# STM32H562 register map
File version: 1.7
CPU: CM33 r0p0, little endian, MPU, FPU, 4 interrupt priority bits
Registers are 32-bit, read-write, reset 0x0 unless marked. A register's access mark holds for its fields unless they carry their own. Offsets are from the block's base; [hi:lo] are bit positions; {n}, {i} and the like mark numbered series; 'fields as' and 'values as' point back to an identical list.

## FMC — Flexible memory controller
Base 0x47000400
Same registers: SEC_FMC 0x57000400
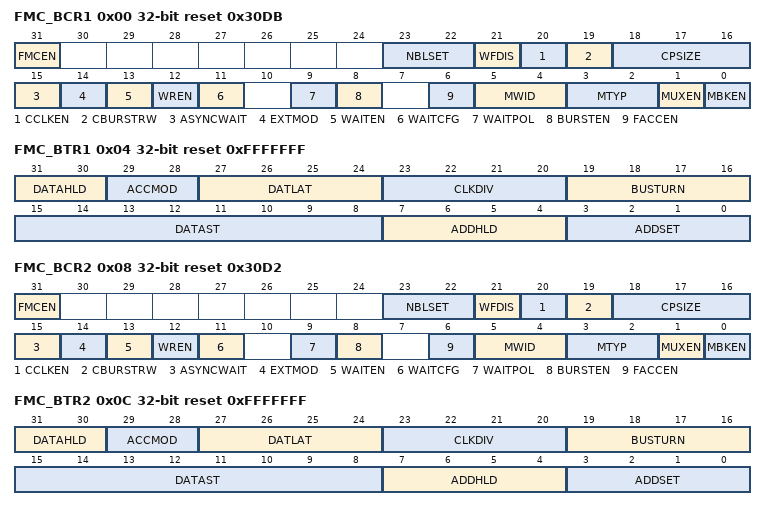
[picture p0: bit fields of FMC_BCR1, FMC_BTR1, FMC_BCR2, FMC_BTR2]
0x00 FMC_BCR1 reset 0x30DB — SRAM/NOR-Flash chip-select control register for bank 1
  [31] FMCEN — FMC controller enable This bit enables or disables the FMC controller. Note: The FMCEN bit of the FMC_BCR2..4 registers is don't care. It is only enabled through the FMC_BCR1 register.
    0=Disable the FMC controller; 1=Enable the FMC controller
  [23:22] NBLSET — Byte lane (NBL) setup These bits configure the NBL setup timing from NBLx low to chip select NEx low.
    0=NBL setup time is 0 AHB clock cycle; 1=NBL setup time is 1 AHB clock cycle; 2=NBL setup time is 2 AHB clock cycles; 3=NBL setup time is 3 AHB clock cycles
  [21] WFDIS — Write FIFO disable This bit disables the Write FIFO used by the FMC controller. Note: The WFDIS bit of the FMC_BCR2..4 registers is don't care. It is only enabled through the FMC_BCR1 register.
    0=Write FIFO enabled (Default after reset); 1=Write FIFO disabled
  [20] CCLKEN — Continuous clock enable This bit enables the FMC_CLK clock output to external memory devices. Note: The CCLKEN bit of the FMC_BCR2..4 registers is don't care. It is only enabled through the FMC_BCR1 register. Bank 1 must be configured in Synchronous mode to generate the FMC_CLK continuous clock. Note: If CCLKEN bit is set, the FMC_CLK clock ratio is specified by CLKDIV value in the FMC_BTR1 register. CLKDIV in FMC_BWTR1 is don't care. Note: If the Synchronous mode is used and CCLKEN bit is set, the synchronous memories connected to other banks than Bank 1 are clocked by the same clock (the CLKDIV value in the FMC_BTR2..4 and FMC_BWTR2..4 registers for other banks has no effect.)
    0=The FMC_CLK is only generated during the synchronous memory access (read/write transaction). The FMC_CLK clock ratio is specified by the programmed CLKDIV value in the FMC_BCRx register (default after reset).; 1=The FMC_CLK is generated continuously during asynchronous and synchronous access. The FMC_CLK clock is activated when the CCLKEN is set.
  [19] CBURSTRW — Write burst enable For PSRAM (CRAM) operating in Burst mode, the bit enables synchronous accesses during write operations. The enable bit for synchronous read accesses is the BURSTEN bit in the FMC_BCRx register.
    0=Write operations are always performed in Asynchronous mode; 1=Write operations are performed in Synchronous mode
  [18:16] CPSIZE — CRAM page size These are used for CellularRAM 1.5 which does not allow burst access to cross the address boundaries between pages. When these bits are configured, the FMC controller splits automatically the burst access when the memory page size is reached (refer to memory datasheet for page size). Others: reserved
    0=No burst split when crossing page boundary (default after reset); 1=128 bytes; 2=256 bytes; 3=512 bytes; 4=1024 bytes
  [15] ASYNCWAIT — Wait signal during asynchronous transfers This bit enables/disables the FMC to use the wait signal even during an asynchronous protocol.
    0=NWAIT signal is not taken in to account when running an asynchronous protocol (default after reset); 1=NWAIT signal is taken in to account when running an asynchronous protocol
  [14] EXTMOD — Extended mode enable This bit enables the FMC to program the write timings for non multiplexed asynchronous accesses inside the FMC_BWTR register, thus resulting in different timings for read and write operations. Note: When the Extended mode is disabled, the FMC can operate in mode 1 or mode 2 as follows: Mode 1 is the default mode when the SRAM/PSRAM memory type is selected (MTYP = 0x0 or 0x01) Mode 2 is the default mode when the NOR memory type is selected (MTYP = 0x10).
    0=values inside FMC_BWTR register are not taken into account (default after reset); 1=values inside FMC_BWTR register are taken into account
  [13] WAITEN — Wait enable bit This bit enables/disables wait-state insertion via the NWAIT signal when accessing the memory in Synchronous mode.
    0=NWAIT signal is disabled (its level not taken into account, no wait state inserted after the programmed Flash latency period); 1=NWAIT signal is enabled (its level is taken into account after the programmed latency period to insert wait states if asserted) (default after reset)
  [12] WREN — Write enable bit This bit indicates whether write operations are enabled/disabled in the bank by the FMC.
    0=Write operations are disabled in the bank by the FMC, an AHB error is reported; 1=Write operations are enabled for the bank by the FMC (default after reset)
  [11] WAITCFG — Wait timing configuration The NWAIT signal indicates whether the data from the memory are valid or if a wait state must be inserted when accessing the memory in Synchronous mode. This configuration bit determines if NWAIT is asserted by the memory one clock cycle before the wait state or during the wait state:
    0=NWAIT signal is active one data cycle before wait state (default after reset); 1=NWAIT signal is active during wait state (not used for PSRAM)
  [9] WAITPOL — Wait signal polarity bit Defines the polarity of the wait signal from memory used for either in Synchronous or Asynchronous mode.
    0=NWAIT active low (default after reset); 1=NWAIT active high
  [8] BURSTEN — Burst enable bit This bit enables/disables synchronous accesses during read operations. It is valid only for synchronous memories operating in Burst mode.
    0=Burst mode disabled (default after reset). Read accesses are performed in Asynchronous mode.; 1=Burst mode enable. Read accesses are performed in Synchronous mode.
  [6] FACCEN — Flash access enable Enables NOR Flash memory access operations.
    0=Corresponding NOR Flash memory access is disabled; 1=Corresponding NOR Flash memory access is enabled (default after reset)
  [5:4] MWID — Memory data bus width Defines the external memory device width, valid for all type of memories.
    0=8 bits; 1=16 bits (default after reset)
  [3:2] MTYP — Memory type Defines the type of external memory attached to the corresponding memory bank.
    0=SRAM/FRAM (default after reset for Bank 2...4); 1=PSRAM (CRAM) / FRAM; 2=NOR Flash/OneNAND Flash (default after reset for Bank 1)
  [1] MUXEN — Address/data multiplexing enable bit When this bit is set, the address and data values are multiplexed on the data bus, valid only with NOR and PSRAM memories:
    0=Address/data non multiplexed; 1=Address/data multiplexed on databus (default after reset)
  [0] MBKEN — Memory bank enable bit Enables the memory bank. After reset Bank1 is enabled, all others are disabled. Accessing a disabled bank causes an ERROR on AHB bus.
    0=Corresponding memory bank is disabled; 1=Corresponding memory bank is enabled
0x04 FMC_BTR1 reset 0xFFFFFFF — SRAM/NOR-Flash chip-select timing register for bank 1
  [31:30] DATAHLD — Data hold phase duration These bits are written by software to define the duration of the data hold phase in HCLK cycles (refer to Figure 21 to Figure 33), used in asynchronous accesses: For read accesses For write accesses
    0=DATAHLD phase duration = 1 HCLK clock cycle (default); 1=DATAHLD phase duration = 2 HCLK clock cycle; 2=DATAHLD phase duration = 3 HCLK clock cycle; 3=DATAHLD phase duration = 4 HCLK clock cycle
  [29:28] ACCMOD — Access mode Specifies the asynchronous access modes as shown in the timing diagrams. These bits are taken into account only when the EXTMOD bit in the FMC_BCRx register is 1.
    0=Access mode A; 1=Access mode B; 2=Access mode C; 3=Access mode D
  [27:24] DATLAT — (see note below bit descriptions): Data latency for synchronous memory For synchronous access with read/write Burst mode enabled (BURSTEN / CBURSTRW bits set), defines the number of memory clock cycles (+2) to issue to the memory before reading/writing the first data: This timing parameter is not expressed in HCLK periods, but in FMC_CLK periods. For asynchronous access, this value is don't care.
    0=Data latency of 2 CLK clock cycles for first burst access; 15=Data latency of 17 CLK clock cycles for first burst access (default value after reset)
  [23:20] CLKDIV — Clock divide ratio (for FMC_CLK signal) Defines the period of FMC_CLK clock output signal, expressed in number of HCLK cycles: In asynchronous NOR Flash, SRAM or PSRAM accesses, this value is don't care. Note: Refer to Section 5.6.5: Synchronous transactions for FMC_CLK divider ratio formula)
    0=FMC_CLK period= 1x HCLK period; 1=FMC_CLK period = 2 HCLK periods; 2=FMC_CLK period = 3 HCLK periods; 15=FMC_CLK period = 16 HCLK periods (default value after reset)
  [19:16] BUSTURN — Bus turnaround phase duration These bits are written by software to add a delay at the end of current read or write transaction to next transaction on the same bank. This delay allows to match the minimum time between consecutive transactions (t EHEL from NEx high to NEx low) and the maximum time needed by the memory to free the data bus after a read access (t EHQZ , chip enable high to output Hi-Z). This delay is recommended for mode D and muxed mode. For non-muxed memory, the bus turnaround delay can be set to minimum value. (BUSTURN + 1)HCLK period greater than or equal max(t EHEL min, t EHQZ max) For FRAM memories, the bus turnaround delay should be configured to match the minimum tPC (precharge time) timings. The bus turnaround delay is inserted between any consecutive transactions on the same bank (read/read, write/write, read/write and write/read) to match the tPC memory timing. The chip select is toggling between any consecutive accesses. (BUSTURN + 1)HCLK period greater than or equal t PC min ...
    0=BUSTURN phase duration = 1 HCLK clock cycle added; 15=BUSTURN phase duration = 16 x HCLK clock cycles added (default value after reset)
  [15:8] DATAST — Data-phase duration These bits are written by software to define the duration of the data phase (refer to Figure 21 to Figure 33), used in asynchronous accesses: ... For each memory type and access mode data-phase duration, refer to the respective figure (Figure 21 to Figure 33). Example: Mode 1, write access, DATAST=1: Data-phase duration= DATAST+1 = 2 HCLK clock cycles. Note: In synchronous accesses, this value is don't care.
    1=DATAST phase duration = 1 HCLK clock cycles; 2=DATAST phase duration = 2 HCLK clock cycles; 255=DATAST phase duration = 255 HCLK clock cycles (default value after reset)
  [7:4] ADDHLD — Address-hold phase duration These bits are written by software to define the duration of the address hold phase (refer to Figure 21 to Figure 33), used in mode D or multiplexed accesses: ... For each access mode address-hold phase duration, refer to the respective figure (Figure 21 to Figure 33). Note: In synchronous accesses, this value is not used, the address hold phase is always 1 memory clock period duration.
    1=ADDHLD phase duration =1 HCLK clock cycle; 2=ADDHLD phase duration = 2 HCLK clock cycle; 15=ADDHLD phase duration = 15 HCLK clock cycles (default value after reset)
  [3:0] ADDSET — Address setup phase duration These bits are written by software to define the duration of the address setup phase (refer to Figure 21 to Figure 33), used in SRAMs, ROMs, asynchronous NOR Flash and PSRAM: ... For each access mode address setup phase duration, refer to the respective figure (Figure 21 to Figure 33). Note: In synchronous accesses, this value is don't care. Note: In Muxed mode or mode D, the minimum value for ADDSET is 1. Note: In mode 1 and PSRAM memory, the minimum value for ADDSET is 1.
    0=ADDSET phase duration = 0 HCLK clock cycle; 15=ADDSET phase duration = 15 HCLK clock cycles (default value after reset)
0x08 FMC_BCR2 reset 0x30D2 — SRAM/NOR-Flash chip-select control register for bank 2
  [31] FMCEN — FMC controller enable This bit enables or disables the FMC controller. Note: The FMCEN bit of the FMC_BCR2..4 registers is don't care. It is only enabled through the FMC_BCR1 register.
    0=Disable the FMC controller; 1=Enable the FMC controller
  [23:22] NBLSET — Byte lane (NBL) setup These bits configure the NBL setup timing from NBLx low to chip select NEx low.
    values as FMC_BCR1.NBLSET
  [21] WFDIS — Write FIFO disable This bit disables the Write FIFO used by the FMC controller. Note: The WFDIS bit of the FMC_BCR2..4 registers is don't care. It is only enabled through the FMC_BCR1 register.
    values as FMC_BCR1.WFDIS
  [20] CCLKEN — Continuous clock enable This bit enables the FMC_CLK clock output to external memory devices. Note: The CCLKEN bit of the FMC_BCR2..4 registers is don't care. It is only enabled through the FMC_BCR1 register. Bank 1 must be configured in Synchronous mode to generate the FMC_CLK continuous clock. Note: If CCLKEN bit is set, the FMC_CLK clock ratio is specified by CLKDIV value in the FMC_BTR1 register. CLKDIV in FMC_BWTR1 is don't care. Note: If the Synchronous mode is used and CCLKEN bit is set, the synchronous memories connected to other banks than Bank 1 are clocked by the same clock (the CLKDIV value in the FMC_BTR2..4 and FMC_BWTR2..4 registers for other banks has no effect.)
    values as FMC_BCR1.CCLKEN
  [19] CBURSTRW — Write burst enable For PSRAM (CRAM) operating in Burst mode, the bit enables synchronous accesses during write operations. The enable bit for synchronous read accesses is the BURSTEN bit in the FMC_BCRx register.
    values as FMC_BCR1.CBURSTRW
  [18:16] CPSIZE — CRAM page size These are used for CellularRAM 1.5 which does not allow burst access to cross the address boundaries between pages. When these bits are configured, the FMC controller splits automatically the burst access when the memory page size is reached (refer to memory datasheet for page size). Others: reserved
    values as FMC_BCR1.CPSIZE
  [15] ASYNCWAIT — Wait signal during asynchronous transfers This bit enables/disables the FMC to use the wait signal even during an asynchronous protocol.
    values as FMC_BCR1.ASYNCWAIT
  [14] EXTMOD — Extended mode enable This bit enables the FMC to program the write timings for non multiplexed asynchronous accesses inside the FMC_BWTR register, thus resulting in different timings for read and write operations. Note: When the Extended mode is disabled, the FMC can operate in mode 1 or mode 2 as follows: Mode 1 is the default mode when the SRAM/PSRAM memory type is selected (MTYP = 0x0 or 0x01) Mode 2 is the default mode when the NOR memory type is selected (MTYP = 0x10).
    values as FMC_BCR1.EXTMOD
  [13] WAITEN — Wait enable bit This bit enables/disables wait-state insertion via the NWAIT signal when accessing the memory in Synchronous mode.
    values as FMC_BCR1.WAITEN
  [12] WREN — Write enable bit This bit indicates whether write operations are enabled/disabled in the bank by the FMC.
    values as FMC_BCR1.WREN
  [11] WAITCFG — Wait timing configuration The NWAIT signal indicates whether the data from the memory are valid or if a wait state must be inserted when accessing the memory in Synchronous mode. This configuration bit determines if NWAIT is asserted by the memory one clock cycle before the wait state or during the wait state:
    values as FMC_BCR1.WAITCFG
  [9] WAITPOL — Wait signal polarity bit Defines the polarity of the wait signal from memory used for either in Synchronous or Asynchronous mode.
    values as FMC_BCR1.WAITPOL
  [8] BURSTEN — Burst enable bit This bit enables/disables synchronous accesses during read operations. It is valid only for synchronous memories operating in Burst mode.
    values as FMC_BCR1.BURSTEN
  [6] FACCEN — Flash access enable Enables NOR Flash memory access operations.
    values as FMC_BCR1.FACCEN
  [5:4] MWID — Memory data bus width Defines the external memory device width, valid for all type of memories.
    0=8 bits
  [3:2] MTYP — Memory type Defines the type of external memory attached to the corresponding memory bank.
    values as FMC_BCR1.MTYP
  [1] MUXEN — Address/data multiplexing enable bit When this bit is set, the address and data values are multiplexed on the data bus, valid only with NOR and PSRAM memories:
    values as FMC_BCR1.MUXEN
  [0] MBKEN — Memory bank enable bit Enables the memory bank. After reset Bank1 is enabled, all others are disabled. Accessing a disabled bank causes an ERROR on AHB bus.
    values as FMC_BCR1.MBKEN
0x0C FMC_BTR2 reset 0xFFFFFFF — SRAM/NOR-Flash chip-select timing register for bank 2
  fields as FMC_BTR1
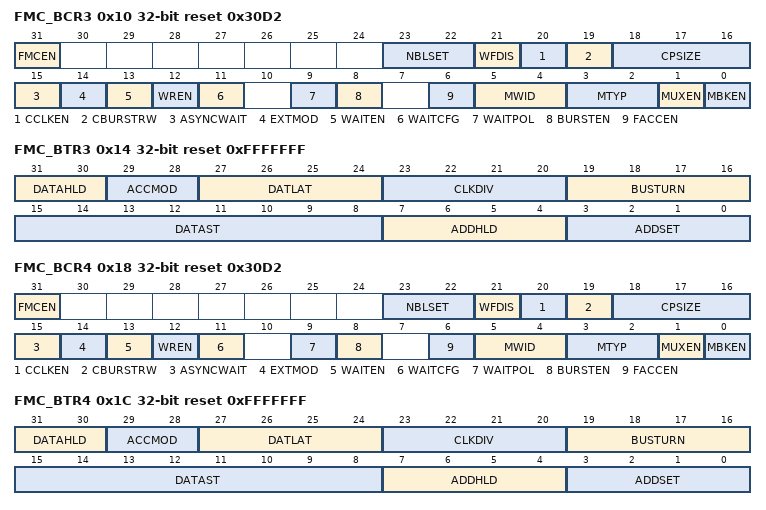
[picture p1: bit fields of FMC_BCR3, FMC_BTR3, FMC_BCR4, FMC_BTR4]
0x10 FMC_BCR3 reset 0x30D2 — SRAM/NOR-Flash chip-select control register for bank 3
  fields as FMC_BCR1
0x14 FMC_BTR3 reset 0xFFFFFFF — SRAM/NOR-Flash chip-select timing register for bank 3
  fields as FMC_BTR1
0x18 FMC_BCR4 reset 0x30D2 — SRAM/NOR-Flash chip-select control register for bank 4
  fields as FMC_BCR1
0x1C FMC_BTR4 reset 0xFFFFFFF — SRAM/NOR-Flash chip-select timing register for bank 4
  fields as FMC_BTR1
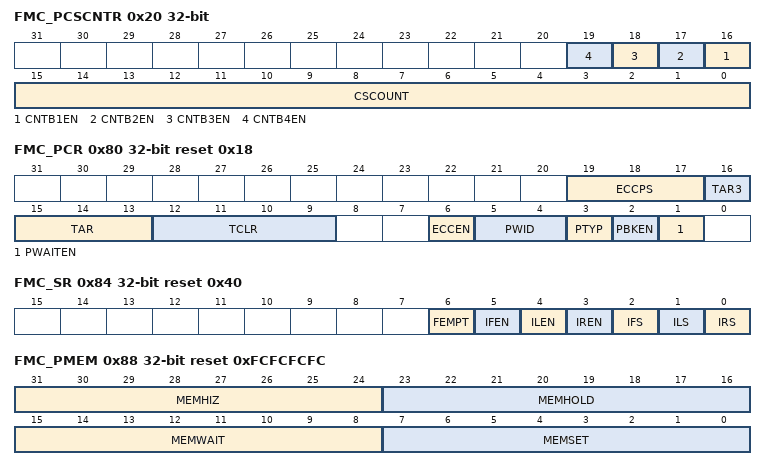
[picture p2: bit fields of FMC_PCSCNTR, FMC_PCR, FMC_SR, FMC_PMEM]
0x20 FMC_PCSCNTR — PSRAM chip select counter register
  [n+15] CNTB{n}EN (n=1..4) — Counter Bank {n} enable This bit enables the chip select counter for PSRAM/NOR Bank {n}.
    0=Counter disabled for Bank {n}; 1=Counter enabled for Bank {n}
  [15:0] CSCOUNT — Chip select counter. These bits are written by software to define the maximum chip select low pulse duration. It is expressed in FMC_CLK cycles for synchronous accesses and in HCLK cycles for asynchronous accesses. The counter is disabled if the programmed value is 0.
0x80 FMC_PCR reset 0x18 — NAND Flash control registers
  [19:17] ECCPS — ECC page size Defines the page size for the extended ECC:
    0=256 bytes; 1=512 bytes; 2=1024 bytes; 3=2048 bytes; 4=4096 bytes; 5=8192 bytes
  [16] TAR3 — ALE to RE delay Sets time from ALE low to RE low in number of AHB clock cycles (HCLK). Time is: t_ar = (TAR + SET + 2) THCLK where THCLK is the HCLK clock period Note: SET is MEMSET or ATTSET according to the addressed space.
    0=1 HCLK cycle (default)
  [15:13] TAR — ALE to RE delay Sets time from ALE low to RE low in number of AHB clock cycles (HCLK). Time is: t_ar = (TAR + SET + 2) THCLK where THCLK is the HCLK clock period Note: SET is MEMSET or ATTSET according to the addressed space.
    0=1 HCLK cycle (default)
  [12:9] TCLR — CLE to RE delay Sets time from CLE low to RE low in number of AHB clock cycles (HCLK). Time is t_clr = (TCLR + SET + 2) THCLK where THCLK is the HCLK clock period Note: SET is MEMSET or ATTSET according to the addressed space.
    0=1 HCLK cycle (default); 15=16 HCLK cycles
  [6] ECCEN — ECC computation logic enable bit
    0=ECC logic is disabled and reset (default after reset),; 1=ECC logic is enabled
  [5:4] PWID — Data bus width Defines the external memory device width.
    0=8 bits; 1=16 bits (default after reset)
  [3] PTYP — Memory type Defines the type of device attached to the corresponding memory bank:
    0=Reserved, must be kept at reset value; 1=NAND Flash (default after reset)
  [2] PBKEN — NAND Flash memory bank enable bit Enables the memory bank. Accessing a disabled memory bank causes an ERROR on AHB bus
    0=Corresponding memory bank is disabled (default after reset); 1=Corresponding memory bank is enabled
  [1] PWAITEN — Wait feature enable bit Enables the Wait feature for the NAND Flash memory bank:
    0=disabled; 1=enabled
0x84 FMC_SR access per field reset 0x40 — FIFO status and interrupt register
  [6] FEMPT ro — FIFO empty Read-only bit that provides the status of the FIFO
    0=FIFO not empty; 1=FIFO empty
  [5] IFEN rw — Interrupt falling edge detection enable bit
    0=Interrupt falling edge detection request disabled; 1=Interrupt falling edge detection request enabled
  [4] ILEN rw — Interrupt high-level detection enable bit
    0=Interrupt high-level detection request disabled; 1=Interrupt high-level detection request enabled
  [3] IREN rw — Interrupt rising edge detection enable bit
    0=Interrupt rising edge detection request disabled; 1=Interrupt rising edge detection request enabled
  [2] IFS rw — Interrupt falling edge status The flag is set by hardware and reset by software. Note: If this bit is written by software to 1 it is set.
    0=No interrupt falling edge occurred; 1=Interrupt falling edge occurred
  [1] ILS rw — Interrupt high-level status The flag is set by hardware and reset by software.
    0=No Interrupt high-level occurred; 1=Interrupt high-level occurred
  [0] IRS rw — Interrupt rising edge status The flag is set by hardware and reset by software. Note: If this bit is written by software to 1 it is set.
    0=No interrupt rising edge occurred; 1=Interrupt rising edge occurred
0x88 FMC_PMEM reset 0xFCFCFCFC — Common memory space timing register
  [31:24] MEMHIZ — Common memory x data bus Hi-Z time Defines the number of HCLK clock cycles during which the data bus is kept Hi-Z after the start of a NAND Flash write access to common memory space on socket. This is only valid for write transactions:
    0=1 HCLK cycle; 254=255 HCLK cycles
  [23:16] MEMHOLD — Common memory hold time Defines the number of HCLK clock cycles for write access and HCLK (+2) clock cycles for read access during which the address is held (and data for write accesses) after the command is deasserted (NWE, NOE), for NAND Flash read or write access to common memory space on socket x:
    1=1 HCLK cycle for write access / 3 HCLK cycles for read access; 254=254 HCLK cycles for write access / 256 HCLK cycles for read access
  [15:8] MEMWAIT — Common memory wait time Defines the minimum number of HCLK (+1) clock cycles to assert the command (NWE, NOE), for NAND Flash read or write access to common memory space on socket. The duration of command assertion is extended if the wait signal (NWAIT) is active (low) at the end of the programmed value of HCLK:
    1=2HCLK cycles (+ wait cycle introduced by deasserting NWAIT); 254=255 HCLK cycles (+ wait cycle introduced by deasserting NWAIT)
  [7:0] MEMSET — Common memory x setup time Defines the number of HCLK (+1) clock cycles to set up the address before the command assertion (NWE, NOE), for NAND Flash read or write access to common memory space on socket x:
    0=1 HCLK cycle; 254=255 HCLK cycles
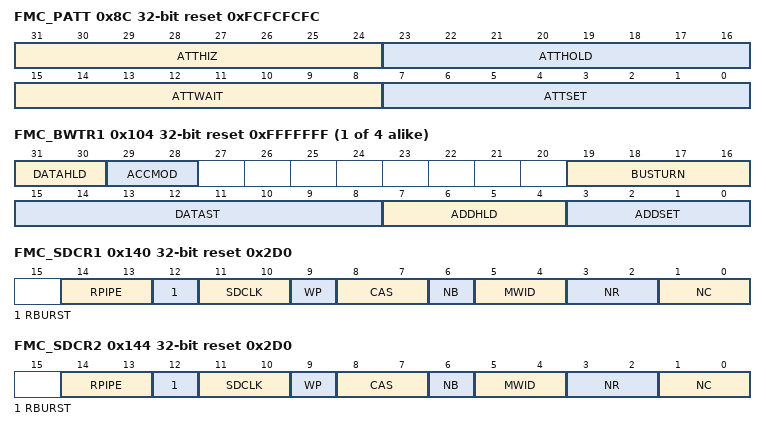
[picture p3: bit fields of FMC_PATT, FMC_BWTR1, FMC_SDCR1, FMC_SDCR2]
0x8C FMC_PATT reset 0xFCFCFCFC — Attribute memory space timing register
  [31:24] ATTHIZ — Attribute memory data bus Hi-Z time Defines the number of HCLK clock cycles during which the data bus is kept in Hi-Z after the start of a NAND Flash write access to attribute memory space on socket. Only valid for writ transaction:
    0=0 HCLK cycle; 254=255 HCLK cycles
  [23:16] ATTHOLD — Attribute memory hold time Defines the number of HCLK clock cycles for write access and HCLK (+2) clock cycles for read access during which the address is held (and data for write access) after the command deassertion (NWE, NOE), for NAND Flash read or write access to attribute memory space on socket:
    values as FMC_PMEM.MEMHOLD
  [15:8] ATTWAIT — Attribute memory wait time Defines the minimum number of HCLK (+1) clock cycles to assert the command (NWE, NOE), for NAND Flash read or write access to attribute memory space on socket x. The duration for command assertion is extended if the wait signal (NWAIT) is active (low) at the end of the programmed value of HCLK:
    1=2 HCLK cycles (+ wait cycle introduced by deassertion of NWAIT); 254=255 HCLK cycles (+ wait cycle introduced by deasserting NWAIT)
  [7:0] ATTSET — Attribute memory setup time Defines the number of HCLK (+1) clock cycles to set up address before the command assertion (NWE, NOE), for NAND Flash read or write access to attribute memory space on socket:
    0=1 HCLK cycle; 254=255 HCLK cycles
0x94 FMC_ECCR ro — ECC result registers
  [31:0] ECC — ECC result This field contains the value computed by the ECC computation logic. Table 99 describes the contents of these bitfields.
{0xFC+8i} FMC_BWTR{i} reset 0xFFFFFFF (i=1..4) — SRAM/NOR-Flash write timing registers {i}
  [31:30] DATAHLD — Data hold phase duration These bits are written by software to define the duration of the data hold phase in HCLK cycles (refer to Figure 21 to Figure 33), used in asynchronous write accesses:
    values as FMC_BTR1.DATAHLD
  [29:28] ACCMOD — Access mode. Specifies the asynchronous access modes as shown in the next timing diagrams.These bits are taken into account only when the EXTMOD bit in the FMC_BCRx register is 1.
    values as FMC_BTR1.ACCMOD
  [19:16] BUSTURN — Bus turnaround phase duration These bits are written by software to add a delay at the end of current write transaction to next transaction on the same bank. For FRAM memories, the bus turnaround delay should be configured to match the minimum t PC (precharge time) timings. The bus turnaround delay is inserted between any consecutive transactions on the same bank (read/read, write/write, read/write and write/read). The chip select is toggling between any consecutive accesses. (BUSTURN + 1)HCLK period greater than or equal tPC min ...
    values as FMC_BTR1.BUSTURN
  [15:8] DATAST — Data-phase duration. These bits are written by software to define the duration of the data phase (refer to Figure 21 to Figure 33), used in asynchronous SRAM, PSRAM and NOR Flash memory accesses: ...
    values as FMC_BTR1.DATAST
  [7:4] ADDHLD — Address-hold phase duration. These bits are written by software to define the duration of the address hold phase (refer to Figure 30 to Figure 33), used in asynchronous multiplexed accesses: ... Note: In synchronous NOR Flash accesses, this value is not used, the address hold phase is always 1 Flash clock period duration.
    1=ADDHLD phase duration = 1 HCLK clock cycle; 2=ADDHLD phase duration = 2 HCLK clock cycle; 15=ADDHLD phase duration = 15 HCLK clock cycles (default value after reset)
  [3:0] ADDSET — Address setup phase duration. These bits are written by software to define the duration of the address setup phase in HCLK cycles (refer to Figure 21 to Figure 33), used in asynchronous accesses: ... Note: In synchronous accesses, this value is not used, the address setup phase is always 1 Flash clock period duration. In muxed mode, the minimum ADDSET value is 1.
    values as FMC_BTR1.ADDSET
0x140 FMC_SDCR1 reset 0x2D0 — SDRAM control registers 1
  [14:13] RPIPE — Read pipe These bits define the delay, in clock cycles, for reading data after CAS latency. Note: The corresponding bits in the FMC_SDCR2 register is read only.
    0=No clock cycle delay; 1=One clock cycle delay; 2=Two clock cycle delay
  [12] RBURST — Burst read This bit enables Burst read mode. The SDRAM controller anticipates the next read commands during the CAS latency and stores data in the Read FIFO. Note: The corresponding bit in the FMC_SDCR2 register is don't care.
    0=single read requests are not managed as bursts; 1=single read requests are always managed as bursts
  [11:10] SDCLK — SDRAM clock configuration These bits define the SDRAM clock period for both SDRAM banks and allow disabling the clock before changing the frequency. In this case the SDRAM must be re-initialized. Note: The corresponding bits in the FMC_SDCR2 register are don't care.
    0=SDCLK clock disabled; 2=SDCLK period = 2 x HCLK periods; 3=SDCLK period = 3 x HCLK periods
  [9] WP — Write protection This bit enables write mode access to the SDRAM bank.
    0=Write accesses allowed; 1=Write accesses ignored
  [8:7] CAS — CAS Latency This bits sets the SDRAM CAS latency in number of memory clock cycles
    1=1 cycle; 2=2 cycles; 3=3 cycles
  [6] NB — Number of internal banks This bit sets the number of internal banks.
    0=Two internal Banks; 1=Four internal Banks
  [5:4] MWID — Memory data bus width. These bits define the memory device width.
    0=8 bits; 1=16 bits
  [3:2] NR — Number of row address bits These bits define the number of bits of a row address.
    0=11 bit; 1=12 bits; 2=13 bits
  [1:0] NC — Number of column address bits These bits define the number of bits of a column address.
    {v}={v+8} bits (v=0..3)
0x144 FMC_SDCR2 reset 0x2D0 — SDRAM control registers 2
  fields as FMC_SDCR1
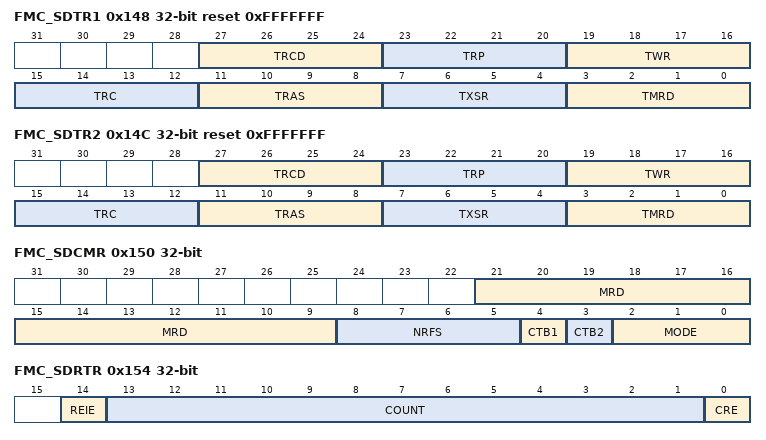
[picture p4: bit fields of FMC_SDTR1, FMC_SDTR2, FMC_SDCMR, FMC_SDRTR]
0x148 FMC_SDTR1 reset 0xFFFFFFF — SDRAM timing registers 1
  [all] fields
    0=1 cycle; 1=2 cycles; 15=16 cycles
  [27:24] TRCD — Row to column delay These bits define the delay between the Activate command and a Read/Write command in number of memory clock cycles. ....
  [23:20] TRP — Row precharge delay These bits define the delay between a Precharge command and another command in number of memory clock cycles. The TRP timing is only configured in the FMC_SDTR1 register. If two SDRAM devices are used, the TRP must be programmed with the timing of the slowest device. .... Note: The corresponding bits in the FMC_SDTR2 register are don't care.
  [19:16] TWR — Recovery delay These bits define the delay between a Write and a Precharge command in number of memory clock cycles. .... Note: TWR must be programmed to match the write recovery time (t WR ) defined in the SDRAM datasheet, and to guarantee that: Note: TWR greater than or equal TRAS TRCD and TWR greater than or equalTRC TRCD TRP Note: Example: TRAS= 4 cycles, TRCD= 2 cycles. So, TWR = 2 cycles. TWR must be programmed to 0x1. Note: If two SDRAM devices are used, the FMC_SDTR1 and FMC_SDTR2 must be programmed with the same TWR timing corresponding to the slowest SDRAM device. Note: If only one SDRAM device is used, the TWR timing must be kept at reset value (0xF) for the not used bank.
  [15:12] TRC — Row cycle delay These bits define the delay between the Refresh command and the Activate command, as well as the delay between two consecutive Refresh commands. It is expressed in number of memory clock cycles. The TRC timing is only configured in the FMC_SDTR1 register. If two SDRAM devices are used, the TRC must be programmed with the timings of the slowest device. .... Note: TRC must match the TRC and TRFC (Auto Refresh period) timings defined in the SDRAM device datasheet. Note: The corresponding bits in the FMC_SDTR2 register are don't care.
  [11:8] TRAS — Self refresh time These bits define the minimum Self-refresh period in number of memory clock cycles. ....
  [7:4] TXSR — Exit Self-refresh delay These bits define the delay from releasing the Self-refresh command to issuing the Activate command in number of memory clock cycles. .... Note: If two SDRAM devices are used, the FMC_SDTR1 and FMC_SDTR2 must be programmed with the same TXSR timing corresponding to the slowest SDRAM device.
  [3:0] TMRD — Load Mode Register to Active These bits define the delay between a Load Mode Register command and an Active or Refresh command in number of memory clock cycles. ....
0x14C FMC_SDTR2 reset 0xFFFFFFF — SDRAM timing registers 2
  fields as FMC_SDTR1
0x150 FMC_SDCMR — SDRAM Command Mode register
  [21:9] MRD — Mode Register definition This 13-bit field defines the SDRAM Mode Register content. The Mode Register is programmed using the Load Mode Register command.
  [8:5] NRFS — Number of Auto-refresh These bits define the number of consecutive Auto-refresh commands issued when MODE = '011'. ....
    0=1 Auto-refresh cycle; 1=2 Auto-refresh cycles; 14=15 Auto-refresh cycles; 15=16 Auto-refresh cycles
  [4] CTB1 — Command Target Bank 1 This bit indicates whether the command will be issued to SDRAM Bank 1 or not.
    0=Command not issued to SDRAM Bank 1; 1=Command issued to SDRAM Bank 1
  [3] CTB2 — Command Target Bank 2 This bit indicates whether the command will be issued to SDRAM Bank 2 or not.
    0=Command not issued to SDRAM Bank 2; 1=Command issued to SDRAM Bank 2
  [2:0] MODE — Command mode These bits define the command issued to the SDRAM device. Note: When a command is issued, at least one Command Target Bank bit ( CTB1 or CTB2) must be set otherwise the command will be ignored. Note: If two SDRAM banks are used, the Auto-refresh and PALL command must be issued simultaneously to the two devices with CTB1 and CTB2 bits set otherwise the command will be ignored. Note: If only one SDRAM bank is used and a command is issued with it's associated CTB bit set, the other CTB bit of the the unused bank must be kept to 0.
    0=Normal Mode; 1=Clock Configuration Enable; 2=PALL ('All Bank Precharge') command; 3=Auto-refresh command; 4=Load Mode Register; 5=Self-refresh command; 6=Power-down command
0x154 FMC_SDRTR access per field — SDRAM refresh timer register
  [14] REIE rw — RES Interrupt Enable
    0=Interrupt is disabled; 1=An Interrupt is generated if RE = 1
  [13:1] COUNT rw — Refresh Timer Count This 13-bit field defines the refresh rate of the SDRAM device. It is expressed in number of memory clock cycles. It must be set at least to 41 SDRAM clock cycles (0x29). Refresh rate = (COUNT + 1) x SDRAM frequency clock COUNT = (SDRAM refresh period / Number of rows) 20
  [0] CRE wo — Clear Refresh error flag This bit is used to clear the Refresh Error Flag (RE) in the Status Register.
    0=no effect; 1=Refresh Error flag is cleared
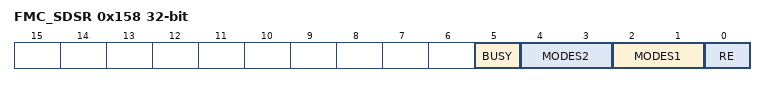
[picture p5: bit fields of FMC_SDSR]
0x158 FMC_SDSR ro — SDRAM status register
  [5] BUSY — Busy status This bit defines the status of the SDRAM controller after a Command Mode request 1; SDRAM Controller is not ready to accept a new request
    0=SDRAM Controller is ready to accept a new request
  [4:3] MODES2 — Status Mode for Bank 2 This bit defines the Status Mode of SDRAM Bank 2.
    0=Normal Mode; 1=Self-refresh mode; 2=Power-down mode
  [2:1] MODES1 — Status Mode for Bank 1 This bit defines the Status Mode of SDRAM Bank 1.
    0=Normal Mode; 1=Self-refresh mode; 2=Power-down mode
  [0] RE — Refresh error flag An interrupt is generated if REIE = 1 and RE = 1
    0=No refresh error has been detected; 1=A refresh error has been detected
